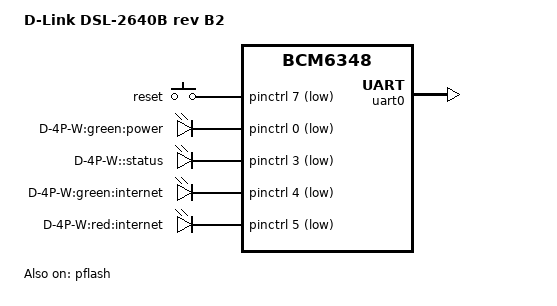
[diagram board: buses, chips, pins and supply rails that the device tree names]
/dts-v1/;

#include "bcm6348.dtsi"

#include <dt-bindings/input/input.h>

/ {
	model = "D-Link DSL-2640B rev B2";
	compatible = "d-link,dsl-2640b-b", "brcm,bcm6348";

	aliases {
		led-boot = &led_power_green;
		led-failsafe = &led_power_green;
		led-running = &led_power_green;
		led-upgrade = &led_power_green;
	};

	chosen {
		bootargs = "rootfstype=squashfs,jffs2 noinitrd console=ttyS0,115200";
		stdout-path = "serial0:115200n8";
	};

	keys {
		compatible = "gpio-keys-polled";
		#address-cells = <1>;
		#size-cells = <0>;
		poll-interval = <20>;

		reset {
			label = "reset";
			gpios = <&pinctrl 7 1>;
			linux,code = <KEY_RESTART>;
			debounce-interval = <60>;
		};
	};

	leds {
		compatible = "gpio-leds";

		led_power_green: power_green {
			label = "D-4P-W:green:power";
			gpios = <&pinctrl 0 1>;
			default-state = "on";
		};
		status {
			label = "D-4P-W::status";
			gpios = <&pinctrl 3 1>;
		};
		inet_green {
			label = "D-4P-W:green:internet";
			gpios = <&pinctrl 4 1>;
		};
		inet_red {
			label = "D-4P-W:red:internet";
			gpios = <&pinctrl 5 1>;
		};
	};
};

&pflash {
	status = "okay";

	partitions {
		compatible = "fixed-partitions";
		#address-cells = <1>;
		#size-cells = <1>;

		cfe@0 {
			label = "CFE";
			reg = <0x000000 0x010000>;
			read-only;
		};

		linux@10000 {
			label = "linux";
			reg = <0x010000 0x3e0000>;
			compatible = "brcm,bcm963xx-imagetag";
		};

		nvram@3f0000 {
			label = "nvram";
			reg = <0x3f0000 0x010000>;
		};
	};
};

&pinctrl {
	pinctrl-names = "default";
	pinctrl-0 = <&pinctrl_pci &pinctrl_ext_mii>;
};

&uart0 {
	status = "okay";
};
